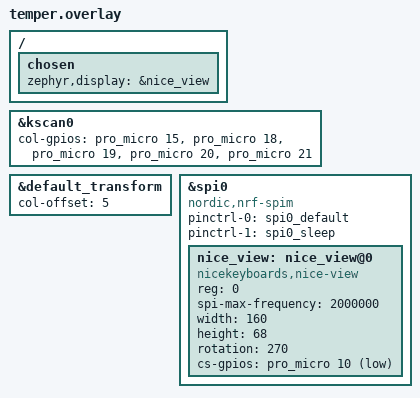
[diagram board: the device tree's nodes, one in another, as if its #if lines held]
/*
 * Copyright (c) 2020 Pete Johanson
 * SPDX-License-Identifier: MIT
 */

#include "temper.dtsi"

// Conditionally apply settings ONLY to the left half
#if IS_LEFT

// Set the nice!view as the main display
/ {
    chosen {
        zephyr,display = &nice_view;
    };
};

// Define keyboard columns for the left side
&kscan0 {
    col-gpios
        = <&pro_micro 21 GPIO_ACTIVE_HIGH>
        , <&pro_micro 20 GPIO_ACTIVE_HIGH>
        , <&pro_micro 19 GPIO_ACTIVE_HIGH>
        , <&pro_micro 18 GPIO_ACTIVE_HIGH>
        , <&pro_micro 15 GPIO_ACTIVE_HIGH>
        ;
};

#endif /* IS_LEFT */


// Conditionally apply settings ONLY to the right half
#if IS_RIGHT

// Set the matrix offset for the right side
&default_transform {
    col-offset = <5>;
};

// Define keyboard columns for the right side
&kscan0 {
    col-gpios
        = <&pro_micro 15 GPIO_ACTIVE_HIGH>
        , <&pro_micro 18 GPIO_ACTIVE_HIGH>
        , <&pro_micro 19 GPIO_ACTIVE_HIGH>
        , <&pro_micro 20 GPIO_ACTIVE_HIGH>
        , <&pro_micro 21 GPIO_ACTIVE_HIGH>
        ;
};

#endif /* IS_RIGHT */


// Define the SPI bus and nice!view display for BOTH sides
// (The display driver will only be active on the side with the 'chosen' property)
&spi0 {
    // This adds the pinctrl properties to fix the original build error
    compatible = "nordic,nrf-spim";
    status = "okay";
    pinctrl-0 = <&spi0_default>;
    pinctrl-1 = <&spi0_sleep>;
    pinctrl-names = "default", "sleep";

    nice_view: nice_view@0 {
        compatible = "nicekeyboards,nice-view";
        reg = <0>;
        spi-max-frequency = <2000000>;
        width = <160>;
        height = <68>;
        rotation = <270>;
        // Using the standard Chip-Select pin for nice!view
        cs-gpios = <&pro_micro 10 GPIO_ACTIVE_LOW>;
        // The conflicting vcom-gpios line has been removed to fix the matrix
    };
};
